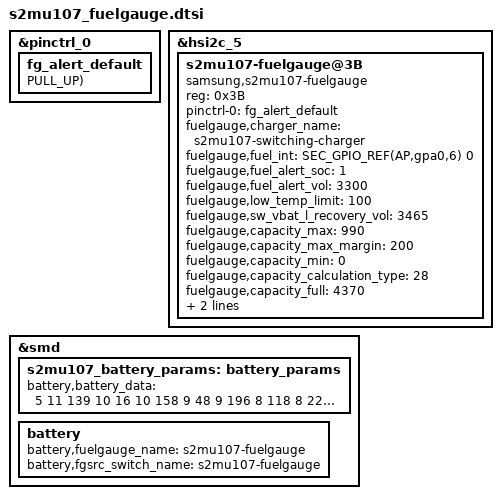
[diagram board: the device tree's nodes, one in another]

&pinctrl_0 {
	fg_alert_default: fg_alert_default {
		GPIO_CONFIG_PUD(AP,gpa0,6, FUNC_INPUT_WAKEUP, PULL_UP);
	};
};

&hsi2c_5 {
	status = "okay";

	s2mu107-fuelgauge@3B {
		compatible = "samsung,s2mu107-fuelgauge";
		reg = <0x3B>;
		pinctrl-names = "default";
		pinctrl-0 = <&fg_alert_default>;
		fuelgauge,charger_name = "s2mu107-switching-charger";
		fuelgauge,fuel_int = <SEC_GPIO_REF(AP,gpa0,6) 0>;
		fuelgauge,fuel_alert_soc = <1>;
		fuelgauge,fuel_alert_vol = <3300>;
		fuelgauge,low_temp_limit = <100>;
		fuelgauge,sw_vbat_l_recovery_vol = <3465>;
		fuelgauge,capacity_max = <990>;
		fuelgauge,capacity_max_margin = <200>;
		fuelgauge,capacity_min = <0>;
		fuelgauge,capacity_calculation_type = <28>;
		fuelgauge,capacity_full = <4370>;
		fuelgauge,type_str = "SDI";
		fuelgauge,fg_log_enable = <1>;
	};
};

&smd {
	s2mu107_battery_params: battery_params {
		battery,battery_data =
			<
			/***** battery data for 4.35 *****/
			/* battery,battery_table3 */
			5 11 139 10 16 10 158 9 48 9
			196 8 118 8 227 7 173 7 65 7
			236 6 182 6 139 6 104 6 76 6
			41 6 0 6 218 5 156 5 131 5
			156 4 133 1 106 8 0 8 150 7
			43 7 193 6 87 6 236 5 130 5
			24 5 174 4 67 4 217 3 111 3
			4 3 154 2 48 2 198 1 91 1
			241 0 135 0 28 0 214 15

			/* battery,battery_table4 */
			10 10 10 10 26 26 25 24 24 24
			23 23 24 24 25 26 27 28 29 31
			36 86

			/* battery,batcap */
			0x48 0x44 0xAC 0x0D /* [0x0E] [0x0F] [0x10] [0x11] */
			/* battery,accum */ 
			0x00 0x08 /* [0x44] [0x45] */

			/* battery,soc_arr_val */
			10519 10000 9480 8961 8442 7923 7404 6885 6366 5847
			5328 4809 4290 3771 3252 2733 2214 1695 1176 657
			138 (-204)

			/* battery,ocv_arr_val */
			43776 43177 42578 42019 41484 40959 40574 39857 39595 39069
			38654 38389 38177 38009 37872 37701 37498 37312 37010 36890
			35763 31899

			/* battery,tunning */
			0x00

			/***** battery data for 4.33 *****/
			/* battery,battery_table3 */
			5	11	139	10	16	10	158	9	48	9
			196	8	118	8	227	7	173	7	65	7
			236	6	182	6	139	6	104	6	76	6
			41	6	0	6	218	5	156	5	131	5
			156	4	133	1	159	8	50	8	197	7
			88	7	235	6	126	6	17	6	165	5
			56	5	203	4	94	4	241	3	132	3
			23	3	170	2	61	2	209	1	100	1
			247	0	138	0	29	0	213	15

			/* battery,battery_table4 */
			26	26	26	26	26	26	25	24	24	24
			23	23	24	24	25	26	27	28	29	31
			36	36

			/* battery,batcap */
			0x68 0x42 0x9A 0x10 /* [0x0E] [0x0F] [0x10] [0x11] */
			/* battery,accum */
			0x00 0x08 /* [0x44] [0x45] */

			/* battery,soc_arr_val */
			10775	10243	9711	9180	8648	8116	7585	7053	6521	5990
			5458	4926	4395	3863	3331	2800	2268	1736	1205	673
			141	(-209)

			/* battery,ocv_arr_val */
			43776	43177	42578	42019	41484	40959	40574	39857	39595	39069
			38654	38389	38177	38009	37872	37701	37498	37312	37010	36890
			35763	31899

			/* battery,tunning */
			0x00

			/***** battery data for 4.31 *****/
			/* battery,battery_table3 */
			5	11	139	10	16	10	158	9	48	9
			196	8	118	8	227	7	173	7	65	7
			236	6	182	6	139	6	104	6	76	6
			41	6	0	6	218	5	156	5	131	5
			156	4	133	1	197	8	86	8	231	7
			121	7	10	7	155	6	44	6	190	5
			79	5	224	4	113	4	2	4	148	3
			37	3	182	2	71	2	217	1	106	1
			251	0	140	0	30	0	212	15

			/* battery,battery_table4 */
			26	26	26	26	26	26	25	24	24	24
			23	23	24	24	25	26	27	28	29	31
			36	36

			/* battery,batcap */
			0x50 0x41 0x54 0x10 /* [0x0E] [0x0F] [0x10] [0x11] */
			/* battery,accum */
			0x00 0x08 /* [0x44] [0x45] */

			/* battery,soc_arr_val */
			10961	10420	9880	9339	8798	8257	7716	7175	6634	6093
			5553	5012	4471	3930	3389	2848	2307	1766	1225	685
			144	(-213)

			/* battery,ocv_arr_val */
			43776	43177	42578	42019	41484	40959	40574	39857	39595	39069
			38654	38389	38177	38009	37872	37701	37498	37312	37010	36890
			35763	31899

			/* battery,tunning */
			0x00

			/***** battery data for 4.29 *****/
			/* battery,battery_table3 */
			5	11	139	10	16	10	158	9	48	9
			196	8	118	8	227	7	173	7	65	7
			236	6	182	6	139	6	104	6	76	6
			41	6	0	6	218	5	156	5	131	5
			156	4	133	1	237	8	124	8	11	8
			154	7	42	7	185	6	72	6	215	5
			103	5	246	4	133	4	21	4	164	3
			51	3	194	2	82	2	225	1	112	1
			255	0	143	0	30	0	212	15

			/* battery,battery_table4 */
			26	26	26	26	26	26	25	24	24	24
			23	23	24	24	25	26	27	28	29	31
			36	36

			/* battery,batcap */
			0x38 0x40 0x0E 0x10 /* [0x0E] [0x0F] [0x10] [0x11] */
			/* battery,accum */
			0x00 0x08 /* [0x44] [0x45] */

			/* battery,soc_arr_val */
			11155	10604	10054	9503	8953	8403	7852	7302	6751	6201
			5650	5100	4550	3999	3449	2898	2348	1798	1247	697
			146	(-217)

			/* battery,ocv_arr_val */
			43776	43177	42578	42019	41484	40959	40574	39857	39595	39069
			38654	38389	38177	38009	37872	37701	37498	37312	37010	36890
			35763	31899

			/* battery,tunning */
			0x00

			/***** battery data for 4.24 *****/
			/* battery,battery_table3 */
			5	11	139	10	16	10	158	9	48	9
			196	8	118	8	227	7	173	7	65	7
			236	6	182	6	139	6	104	6	76	6
			41	6	0	6	218	5	156	5	131	5
			156	4	133	1	77	9	215	8	98	8
			236	7	119	7	1	7	140	6	22	6
			161	5	43	5	182	4	64	4	203	3
			86	3	224	2	107	2	245	1	128	1
			10	1	149	0	31	0	210	15

			/* battery,battery_table4 */
			26	26	26	26	26	26	25	24	24	24
			23	23	24	24	25	26	27	28	29	31
			36	36

			/* battery,batcap */
			0x08 0x3E 0x82 0x0F /* [0x0E] [0x0F] [0x10] [0x11] */
			/* battery,accum */
			0x00 0x08 /* [0x44] [0x45] */

			/* battery,soc_arr_val */
			11623	11050	10476	9903	9329	8756	8182	7608	7035	6461
			5888	5314	4741	4167	3594	3020	2447	1873	1300	726
			152	(-226)

			/* battery,ocv_arr_val */
			43776	43177	42578	42019	41484	40959	40574	39857	39595	39069
			38654	38389	38177	38009	37872	37701	37498	37312	37010	36890
			35763	31899

			/* battery,tunning */
			0x00
			>;
	};
};

&smd {
		battery {
			battery,fuelgauge_name = "s2mu107-fuelgauge";
			battery,fgsrc_switch_name = "s2mu107-fuelgauge";
		};
};

/* /home/dpi/qb5_8815/workspace/P4_1716/android/kernel/kmodule/battery/fuelgauge/s2mu107_fuelgauge/s2mu107_fuelgauge.a71x.dtsi */

&smd {
	battery_params {
		battery,battery_data =
			<
			/***** battery data for 4.35 *****/
			/* battery,battery_table3 */
			5 11 139 10 16 10 158 9 48 9
			196 8 118 8 227 7 173 7 65 7
			236 6 182 6 139 6 104 6 76 6
			41 6 0 6 218 5 156 5 131 5
			156 4 133 1 106 8 0 8 150 7
			43 7 193 6 87 6 236 5 130 5
			24 5 174 4 67 4 217 3 111 3
			4 3 154 2 48 2 198 1 91 1
			241 0 135 0 28 0 214 15

			/* battery,battery_table4 */
			10 10 10 10 26 26 25 24 24 24
			23 23 24 24 25 26 27 28 29 31
			36 86

			/* battery,batcap */
			0x48 0x44 0xAC 0x0D /* [0x0E] [0x0F] [0x10] [0x11] */
			/* battery,accum */ 
			0x00 0x08 /* [0x44] [0x45] */

			/* battery,soc_arr_val */
			10519 10000 9480 8961 8442 7923 7404 6885 6366 5847
			5328 4809 4290 3771 3252 2733 2214 1695 1176 657
			138 (-204)

			/* battery,ocv_arr_val */
			43776 43177 42578 42019 41484 40959 40574 39857 39595 39069
			38654 38389 38177 38009 37872 37701 37498 37312 37010 36890
			35763 31899

			/* battery,tunning */
			0x00

			/***** battery data for 4.33 *****/
			/* battery,battery_table3 */
			5	11	139	10	16	10	158	9	48	9
			196	8	118	8	227	7	173	7	65	7
			236	6	182	6	139	6	104	6	76	6
			41	6	0	6	218	5	156	5	131	5
			156	4	133	1	159	8	50	8	197	7
			88	7	235	6	126	6	17	6	165	5
			56	5	203	4	94	4	241	3	132	3
			23	3	170	2	61	2	209	1	100	1
			247	0	138	0	29	0	213	15

			/* battery,battery_table4 */
			26	26	26	26	26	26	25	24	24	24
			23	23	24	24	25	26	27	28	29	31
			36	36

			/* battery,batcap */
			0x68 0x42 0x9A 0x10 /* [0x0E] [0x0F] [0x10] [0x11] */
			/* battery,accum */
			0x00 0x08 /* [0x44] [0x45] */

			/* battery,soc_arr_val */
			10775	10243	9711	9180	8648	8116	7585	7053	6521	5990
			5458	4926	4395	3863	3331	2800	2268	1736	1205	673
			141	(-209)

			/* battery,ocv_arr_val */
			43776	43177	42578	42019	41484	40959	40574	39857	39595	39069
			38654	38389	38177	38009	37872	37701	37498	37312	37010	36890
			35763	31899

			/* battery,tunning */
			0x00

			/***** battery data for 4.31 *****/
			/* battery,battery_table3 */
			5	11	139	10	16	10	158	9	48	9
			196	8	118	8	227	7	173	7	65	7
			236	6	182	6	139	6	104	6	76	6
			41	6	0	6	218	5	156	5	131	5
			156	4	133	1	197	8	86	8	231	7
			121	7	10	7	155	6	44	6	190	5
			79	5	224	4	113	4	2	4	148	3
			37	3	182	2	71	2	217	1	106	1
			251	0	140	0	30	0	212	15

			/* battery,battery_table4 */
			26	26	26	26	26	26	25	24	24	24
			23	23	24	24	25	26	27	28	29	31
			36	36

			/* battery,batcap */
			0x50 0x41 0x54 0x10 /* [0x0E] [0x0F] [0x10] [0x11] */
			/* battery,accum */
			0x00 0x08 /* [0x44] [0x45] */

			/* battery,soc_arr_val */
			10961	10420	9880	9339	8798	8257	7716	7175	6634	6093
			5553	5012	4471	3930	3389	2848	2307	1766	1225	685
			144	(-213)

			/* battery,ocv_arr_val */
			43776	43177	42578	42019	41484	40959	40574	39857	39595	39069
			38654	38389	38177	38009	37872	37701	37498	37312	37010	36890
			35763	31899

			/* battery,tunning */
			0x00

			/***** battery data for 4.29 *****/
			/* battery,battery_table3 */
			5	11	139	10	16	10	158	9	48	9
			196	8	118	8	227	7	173	7	65	7
			236	6	182	6	139	6	104	6	76	6
			41	6	0	6	218	5	156	5	131	5
			156	4	133	1	237	8	124	8	11	8
			154	7	42	7	185	6	72	6	215	5
			103	5	246	4	133	4	21	4	164	3
			51	3	194	2	82	2	225	1	112	1
			255	0	143	0	30	0	212	15

			/* battery,battery_table4 */
			26	26	26	26	26	26	25	24	24	24
			23	23	24	24	25	26	27	28	29	31
			36	36

			/* battery,batcap */
			0x38 0x40 0x0E 0x10 /* [0x0E] [0x0F] [0x10] [0x11] */
			/* battery,accum */
			0x00 0x08 /* [0x44] [0x45] */

			/* battery,soc_arr_val */
			11155	10604	10054	9503	8953	8403	7852	7302	6751	6201
			5650	5100	4550	3999	3449	2898	2348	1798	1247	697
			146	(-217)

			/* battery,ocv_arr_val */
			43776	43177	42578	42019	41484	40959	40574	39857	39595	39069
			38654	38389	38177	38009	37872	37701	37498	37312	37010	36890
			35763	31899

			/* battery,tunning */
			0x00

			/***** battery data for 4.24 *****/
			/* battery,battery_table3 */
			5	11	139	10	16	10	158	9	48	9
			196	8	118	8	227	7	173	7	65	7
			236	6	182	6	139	6	104	6	76	6
			41	6	0	6	218	5	156	5	131	5
			156	4	133	1	77	9	215	8	98	8
			236	7	119	7	1	7	140	6	22	6
			161	5	43	5	182	4	64	4	203	3
			86	3	224	2	107	2	245	1	128	1
			10	1	149	0	31	0	210	15

			/* battery,battery_table4 */
			26	26	26	26	26	26	25	24	24	24
			23	23	24	24	25	26	27	28	29	31
			36	36

			/* battery,batcap */
			0x08 0x3E 0x82 0x0F /* [0x0E] [0x0F] [0x10] [0x11] */
			/* battery,accum */
			0x00 0x08 /* [0x44] [0x45] */

			/* battery,soc_arr_val */
			11623	11050	10476	9903	9329	8756	8182	7608	7035	6461
			5888	5314	4741	4167	3594	3020	2447	1873	1300	726
			152	(-226)

			/* battery,ocv_arr_val */
			43776	43177	42578	42019	41484	40959	40574	39857	39595	39069
			38654	38389	38177	38009	37872	37701	37498	37312	37010	36890
			35763	31899

			/* battery,tunning */
			0x00
			>;
	};
};
